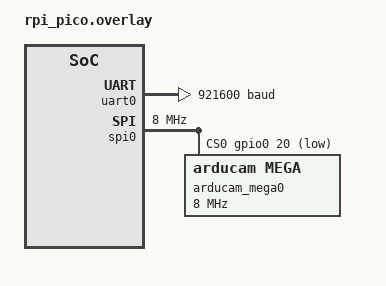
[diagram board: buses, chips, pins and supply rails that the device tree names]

&uart0 {
    current-speed = <921600>;
};

&spi0 {
    clock-frequency = <8000000>;
    cs-gpios = <&gpio0 20 GPIO_ACTIVE_LOW>;
    arducam_mega0: arducam-mega0@0 {
        compatible = "arducam,mega";
        reg = <0>;
        spi-max-frequency = <8000000>;
        status = "okay";
    };
};

&pinctrl {
	spi1_default: spi1_default {
		group1 {
			pinmux = <SPI1_CSN_P9>, <SPI1_SCK_P10>, <SPI1_TX_P11>,<SPI1_RX_P12>;
			input-enable;
		};
	};
};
